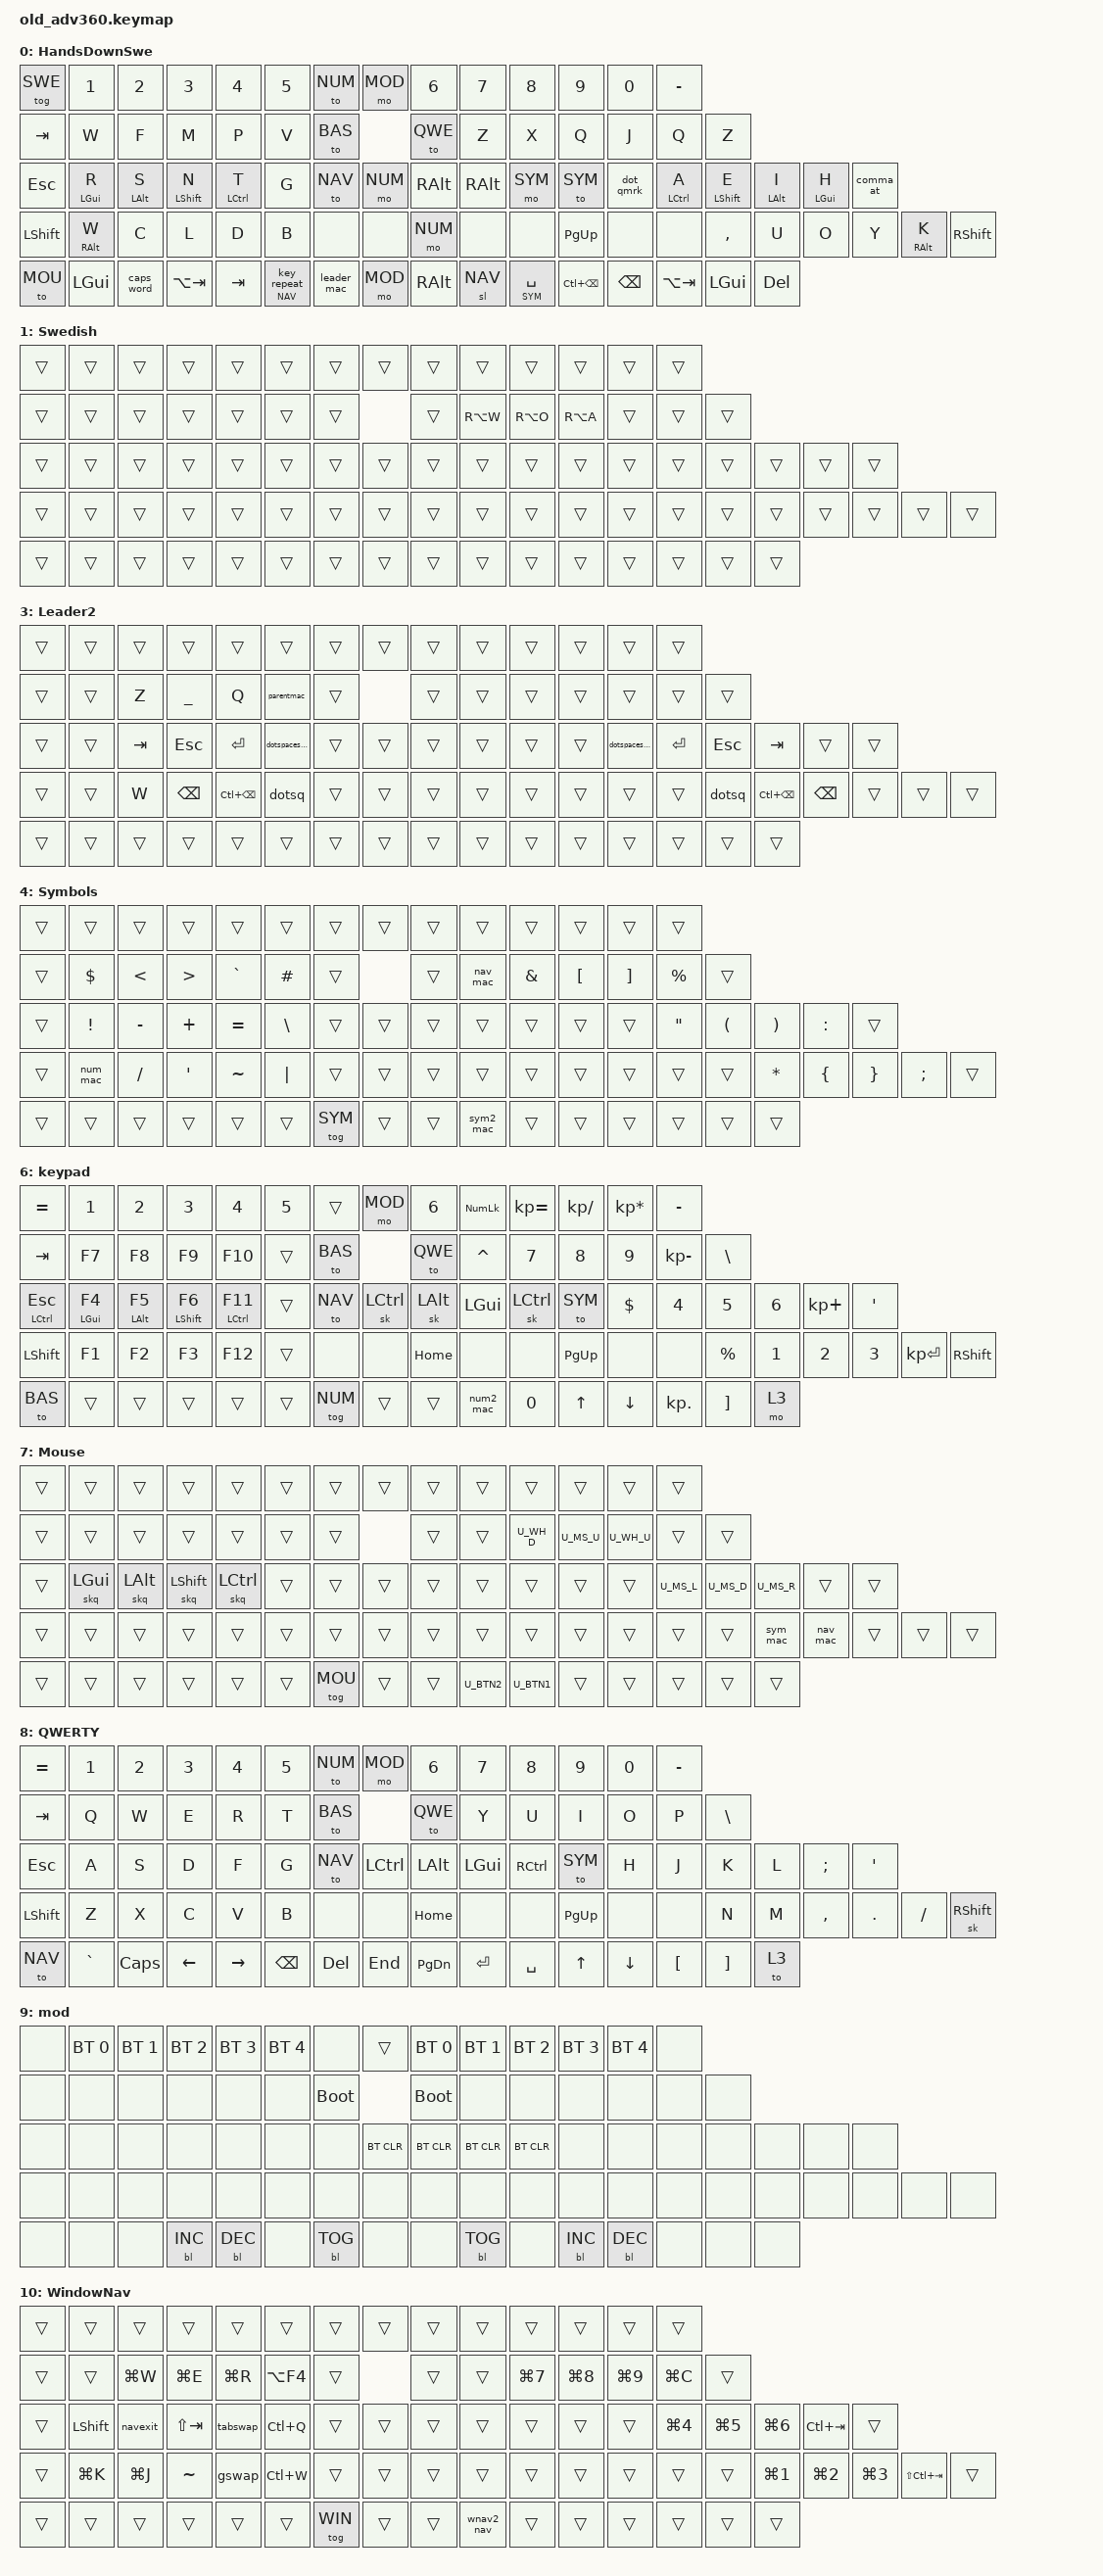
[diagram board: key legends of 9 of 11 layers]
#include <behaviors.dtsi>
#include <dt-bindings/led/led.h>
#include <dt-bindings/zmk/backlight.h>
#include <dt-bindings/zmk/bt.h>
#include <dt-bindings/zmk/keys.h>
#include <dt-bindings/zmk/rgb.h>
#include "mouse.dtsi"
#include "../zmk-nodefree-config/helper.h"
#include "keypos_adv360.h"

#define BAS 0
#define SWE 1
#define LE1 2
#define LE2 3
#define SYM 4
#define NAV 5
#define NUM 6
#define MOU 7
#define QWE 8
#define MOD 9
#define WIN 10




/ {
    behaviors {
        tabswap: tabs {
            compatible = "zmk,behavior-tri-state";
            #binding-cells = <0>;
            label = "tabs";
            bindings = <&kt LALT>, <&kp TAB>, <&kt LALT>;
            ignored-key-positions = <LM2>;
        };
        gswap: tabg {
            compatible = "zmk,behavior-tri-state";
            #binding-cells = <0>;
            label = "tabg";
            bindings = <&kt LALT>, <&kp GRAVE>, <&kt LALT>;
            ignored-key-positions = <LB2>;
        };

        gqt: global-quick-tap {
            compatible = "zmk,behavior-hold-tap";
            label = "GLOBAL_QUICK_TAP";
            #binding-cells = <2>;
            flavor = "tap-preferred";
            tapping-term-ms = <225>;
            quick-tap-ms = <200>;
            global-quick-tap;
            bindings =
                <&kp>,
                <&kp>;
        };
        gql: global-quick-tap-layer {
            compatible = "zmk,behavior-hold-tap";
            label = "GLOBAL_QUICK_TAP_LAYER";
            #binding-cells = <2>;
            flavor = "tap-preferred";
            tapping-term-ms = <225>;
            quick-tap-ms = <200>;
            global-quick-tap;
            bindings =
                <&mo>,
                <&kp>;
        };
        gqr: global-quick-tap-layer-repeat {
            compatible = "zmk,behavior-hold-tap";
            label = "GLOBAL_QUICK_TAP_LAYER_REPEAT";
            #binding-cells = <2>;
            flavor = "tap-preferred";
            tapping-term-ms = <225>;
            quick-tap-ms = <200>;
            global-quick-tap;
            bindings =
                <&mo>,
                <&key_repeat>;
        };
        dot_qmrk: dot_qmrk {
            compatible = "zmk,behavior-mod-morph";
            label = "dot_qmrk";
            #binding-cells = <0>;
            bindings =
                <&kp DOT>,
                <&kp QUESTION>;

            mods = <(MOD_LSFT|MOD_RSFT)>;
        };
        comma_at: comma_at {
            compatible = "zmk,behavior-mod-morph";
            label = "comma_at";
            #binding-cells = <0>;
            bindings =
                <&kp COMMA>,
                <&kp AT>;

            mods = <(MOD_LSFT|MOD_RSFT)>;
        };
        comma_excl: comma_excl {
            compatible = "zmk,behavior-mod-morph";
            label = "comma_excl";
            #binding-cells = <0>;
            bindings =
                <&kp COMMA>,
                <&kp EXCL>;

            mods = <(MOD_LSFT|MOD_RSFT)>;
        };
        lpar_bsh: lpar_bsh {
            compatible = "zmk,behavior-mod-morph";
            label = "lpar_bsh";
            #binding-cells = <0>;
            bindings =
                <&kp LEFT_PARENTHESIS>,
                <&kp BACKSLASH>;

            mods = <(MOD_LSFT|MOD_RSFT)>;
        };
        rpar_fsh: rpar_fsh {
            compatible = "zmk,behavior-mod-morph";
            label = "rpar_fsh";
            #binding-cells = <0>;
            bindings =
                <&kp RIGHT_PARENTHESIS>,
                <&kp SLASH>;

            mods = <(MOD_LSFT|MOD_RSFT)>;
        };
        under_minus: under_minus {
            compatible = "zmk,behavior-mod-morph";
            label = "under_minus";
            #binding-cells = <0>;
            bindings =
                <&kp UNDERSCORE>,
                <&kp MINUS>;

            mods = <(MOD_LSFT|MOD_RSFT)>;
        };
        leader_mac: behavior_macro_1 {
            compatible = "zmk,behavior-macro";
            label = "MACRO1";
            tap-ms = <0>;
            wait-ms = <0>;
            #binding-cells = <0>;
            bindings = < &sl LE1 >;
        };
        sym_mac: behavior_macro_2 {
            compatible = "zmk,behavior-macro";
            label = "MACRO2";
            tap-ms = <0>;
            wait-ms = <0>;
            #binding-cells = <0>;
            bindings = < &sl SYM >;
        };
        nav_mac: behavior_macro_3 {
            compatible = "zmk,behavior-macro";
            label = "MACRO3";
            tap-ms = <0>;
            wait-ms = <0>;
            #binding-cells = <0>;
            bindings = < &sl NAV >;
        };
        num_mac: behavior_macro_4 {
            compatible = "zmk,behavior-macro";
            label = "MACRO4";
            tap-ms = <0>;
            wait-ms = <0>;
            #binding-cells = <0>;
            bindings = < &sl NUM >;
        };
        lead2_mac: behavior_macro_5 {
            compatible = "zmk,behavior-macro";
            label = "MACRO5";
            tap-ms = <0>;
            wait-ms = <0>;
            #binding-cells = <0>;
            bindings = < &sl LE2 >;
        };
        sym2_mac: behavior_macro_6 {
            compatible = "zmk,behavior-macro";
            label = "MACRO6";
            tap-ms = <0>;
            wait-ms = <0>;
            #binding-cells = <0>;
            bindings = < &tog SYM  &sl NAV>;
        };
        nav2_mac: behavior_macro_7 {
            compatible = "zmk,behavior-macro";
            label = "MACRO7";
            tap-ms = <0>;
            wait-ms = <0>;
            #binding-cells = <0>;
            bindings = < &tog NAV  &sl LE2>;
        };
        num2_mac: behavior_macro_8 {
            compatible = "zmk,behavior-macro";
            label = "MACRO8";
            tap-ms = <0>;
            wait-ms = <0>;
            #binding-cells = <0>;
            bindings = < &tog NUM  &sl NAV>;
        };

        skq: sticky_key_quick_release {
            compatible = "zmk,behavior-sticky-key";
            label = "STICKY_KEY_QUICK_RELEASE";
            #binding-cells = <1>;
            bindings = <&kp>;
            release-after-ms = <1000>;
            quick-release;
            ignore-modifiers;
        };
        gnum: behavior_macro_9 {
            compatible = "zmk,behavior-macro";
            label = "MACRO9";
            #binding-cells = <0>;
            bindings = < &skq LEFT_SHIFT >, < &sl NUM >;
        };
        navexit: behavior_macro_10 {
            compatible = "zmk,behavior-macro";
            label = "MACRO10";
            #binding-cells = <0>;
            bindings = < &kp ENTER  &tog WIN >;
        };
        dotspaceshift: behavior_macro_11 {
            compatible = "zmk,behavior-macro";
            label = "MACRO11";
            tap-ms = <0>;
            wait-ms = <0>;
            #binding-cells = <0>;
            bindings = < &kp DOT  &kp SPACE  &skq LEFT_SHIFT >;
        };
        dotsq: behavior_macro_12 {
            compatible = "zmk,behavior-macro";
            label = "MACRO12";
            tap-ms = <0>;
            wait-ms = <0>;
            #binding-cells = <0>;
            bindings = < &kp QUESTION  &kp SPACE  &skq LEFT_SHIFT >;
        };
        parentmac: behavior_macro_13 {
            compatible = "zmk,behavior-macro";
            label = "MACRO13";
            tap-ms = <0>;
            wait-ms = <0>;
            #binding-cells = <0>;
            bindings = < &kp DOT &kp DOT &kp SLASH >;
        };
        leadcaps: behavior_macro_14 {
            compatible = "zmk,behavior-macro";
            label = "MACRO14";
            tap-ms = <0>;
            wait-ms = <0>;
            #binding-cells = <0>;
            bindings = < &tog LE2  &caps_word >;
        };
        cwr: releasable_caps_word {
            compatible = "zmk,behavior-macro";
            label = "RELEASABLECAPSWORD";
            tap-ms = <0>;
            wait-ms = <0>;
            #binding-cells = <0>;
            bindings = <&macro_tap &kp F17 &caps_word>;
        };
        swe: behavior_macro_15 {
            compatible = "zmk,behavior-macro";
            label = "MACRO15";
            tap-ms = <0>;
            wait-ms = <0>;
            #binding-cells = <0>;
            bindings = <&macro_tap &kp F17 &tog SWE>;
        };
        wnav2_nav: behavior_macro_16 {
            compatible = "zmk,behavior-macro";
            label = "MACRO16";
            tap-ms = <0>;
            wait-ms = <0>;
            #binding-cells = <0>;
            bindings = < &tog WIN  &sl NAV >;
        };

    };

    keymap {
        compatible = "zmk,keymap";

        HandsDownSwe {
            bindings = <
        &tog SWE           &kp N1           &kp N2             &kp N3               &kp N4    &kp N5         &to NUM       &mo MOD     &kp N6        &kp N7            &kp N8             &kp N9            &kp N0  &kp MINUS
       &kp TAB            &kp W            &kp F              &kp M                &kp P     &kp V         &to BAS  &to QWE  &kp Z  &kp X  &kp Q      &kp J             &kp Q      &kp Z
 &kp ESCAPE  &gqt LEFT_GUI R  &gqt LEFT_ALT S  &gqt LEFT_SHIFT N  &gqt LEFT_CONTROL T     &kp G         &to NAV  &mo NUM  &kp RALT   &kp RALT  &mo SYM   &to SYM     &dot_qmrk  &gqt LEFT_CONTROL A  &gqt LEFT_SHIFT E  &gqt LEFT_ALT I  &gqt LEFT_GUI H      &comma_at
&kp LEFT_SHIFT      &gqt RALT W            &kp C              &kp L                &kp D     &kp B         &none       &none      &mo NUM         &none             &none          &kp PG_UP             &none      &none  &kp COMMA                &kp U              &kp O            &kp Y      &gqt RALT K  &kp RIGHT_SHIFT
    &to MOU     &kp LEFT_GUI       &caps_word            &kp LA(TAB)          &kp TAB  &gqr NAV 0  &leader_mac       &mo MOD   &kp RALT  &sl NAV         &gql SYM SPACE  &kp LC(BACKSPACE)     &kp BACKSPACE  &kp LA(TAB)  &kp LEFT_GUI           &kp DELETE
            >;
        };
        Swedish {
            bindings = <
&trans  &trans  &trans  &trans  &trans  &trans  &trans /**/ &trans  &trans  &trans  &trans  &trans  &trans  &trans
&trans  &trans  &trans  &trans  &trans  &trans  &trans /**/ &trans  &kp RA(W)  &kp RA(O)  &kp RA(A)   &trans  &trans  &trans
&trans  &trans  &trans  &trans  &trans  &trans  &trans  &trans  &trans /**/ &trans  &trans  &trans  &trans  &trans  &trans  &trans  &trans  &trans
&trans  &trans  &trans  &trans  &trans  &trans  &trans  &trans  &trans  &trans /**/ &trans  &trans  &trans  &trans  &trans  &trans  &trans  &trans  &trans  &trans
&trans  &trans  &trans  &trans  &trans  &trans  &trans  &trans /**/ &trans  &trans  &trans  &trans  &trans  &trans  &trans  &trans
            >;
        };

        Leader {
            bindings = <
&trans  &trans  &trans  &trans  &trans  &trans  &trans /**/ &trans  &trans  &trans  &trans  &trans  &trans  &trans
&trans  &trans  &tog NUM  &tog SYM  &tog NAV  &swe  &trans /**/ &trans  &swe  &tog NAV  &tog SYM  &tog NUM  &trans  &trans
&trans  &skq LEFT_GUI  &skq LEFT_ALT  &skq LEFT_SHIFT  &skq LEFT_CONTROL  &num_mac  &trans  &trans  &trans /**/ &trans    &trans   &trans  &num_mac  &skq LEFT_CONTROL  &skq LEFT_SHIFT  &skq LEFT_ALT  &skq LEFT_GUI  &trans
&trans  &tog WIN  &cwr  &nav_mac  &sym_mac  &tog MOU  &trans  &trans  &trans  &trans /**/ &trans  &trans  &trans  &trans  &tog MOU    &sym_mac  &nav_mac  &cwr  &tog WIN  &trans
&trans  &trans  &trans  &trans  &trans  &trans  &trans  &trans /**/ &trans  &trans  &trans  &trans  &trans  &trans  &trans
            >;
        };
        Leader2 {
            bindings = <
&trans  &trans  &trans  &trans  &trans  &trans  &trans /**/ &trans  &trans  &trans  &trans  &trans  &trans  &trans
&trans  &trans  &kp Z  &kp UNDERSCORE  &kp Q  &parentmac  &trans /**/ &trans  &trans  &trans  &trans  &trans  &trans  &trans
&trans  &trans  &kp TAB  &kp ESCAPE  &kp ENTER  &dotspaceshift  &trans  &trans  &trans /**/ &trans  &trans  &trans  &dotspaceshift  &kp ENTER  &kp ESCAPE  &kp TAB  &trans  &trans
&trans  &trans  &kp W  &kp BACKSPACE  &kp LC(BACKSPACE)  &dotsq  &trans  &trans  &trans  &trans /**/ &trans  &trans  &trans  &trans  &dotsq  &kp LC(BACKSPACE)  &kp BACKSPACE  &trans  &trans  &trans
&trans  &trans  &trans  &trans  &trans  &trans  &trans  &trans /**/ &trans  &trans  &trans  &trans  &trans  &trans  &trans  &trans
            >;
        };

        Symbols {
            bindings = <
&trans           &trans         &trans            &trans     &trans            &trans  &trans  &trans  &trans         &trans            &trans             &trans       &trans  &trans
&trans       &kp DOLLAR  &kp LESS_THAN  &kp GREATER_THAN  &kp GRAVE  &kp HASH  &trans  &trans  &nav_mac  &kp AMPERSAND  &kp LEFT_BRACKET  &kp RIGHT_BRACKET  &kp PERCENT  &trans
&trans  &kp EXCLAMATION      &kp MINUS          &kp PLUS  &kp EQUAL     &kp BACKSLASH  &trans  &trans  &trans                                              &trans       &trans  &trans  &trans  &kp DOUBLE_QUOTES  &kp LEFT_PARENTHESIS  &kp RIGHT_PARENTHESIS  &kp COLON  &trans
&trans        &num_mac      &kp SLASH          &kp SINGLE_QUOTE  &kp TILDE          &kp PIPE  &trans  &trans  &trans         &trans            &trans             &trans       &trans  &trans  &trans       &kp ASTERISK        &kp LEFT_BRACE        &kp RIGHT_BRACE     &kp SEMI  &trans
&trans           &trans         &trans            &trans     &trans            &trans  &tog SYM  &trans  &trans          &sym2_mac            &trans             &trans       &trans  &trans  &trans             &trans
            >;
        };

        Nav {
            bindings = <
       &kp C_BRI_UP     &kp C_BRI_DN    &kp C_PLAY_PAUSE  &kp C_VOLUME_DOWN  &kp C_VOLUME_UP  &kp K_MUTE   &to NUM   &mo MOD  &kp F7   &kp F8     &kp F9          &kp F10        &kp F11       &kp F12
&trans    &kp LC(Q)           &kp LC(BACKSPACE)          &kp UNDERSCORE        &kp AT   &kp LC(T)   &to BAS  &to QWE  &trans  &kp TAB  &kp ENTER        &kp TAB  &trans        &trans
&trans   &skq LEFT_GUI  &skq LEFT_ALT  &skq LEFT_SHIFT  &skq LEFT_CONTROL  &trans  &trans  &trans  &trans  &trans  &trans  &trans  &kp LEFT  &kp DOWN         &kp UP    &kp RIGHT   &trans  &trans
     &trans           &kp BACKSPACE  &kp TAB  &kp ESCAPE  &kp ENTER &trans  &trans   &trans     &trans           &trans         &trans        &trans   &trans  &trans        &trans  &kp HOME  &kp END  &kp PAGE_DOWN  &kp PAGE_UP  &trans
      &trans        &kp C_REWIND  &kp C_FAST_FORWARD         &kp C_PREV  &kp PRINTSCREEN      &trans  &trans  &trans  &trans   &tog NAV     &trans  &trans  &trans   &trans     &to 0
            >;
        };

        keypad {
            bindings = <
           &kp EQUAL            &kp N1        &kp N2        &kp N3          &kp N4         &kp N5     &trans             &mo MOD        &kp N6   &kp KP_NUM  &kp KP_EQUAL  &kp KP_DIVIDE   &kp KP_MULTIPLY   &kp MINUS
             &kp TAB            &kp F7        &kp F8        &kp F9         &kp F10         &trans      &to BAS  &to QWE        &kp CARET       &kp N7        &kp N8         &kp N9      &kp KP_MINUS    &kp BSLH
&mt LEFT_CONTROL ESC            &mt LEFT_GUI F4        &mt LEFT_ALT F5        &mt LEFT_SHIFT F6         &mt LEFT_CONTROL F11         &trans      &to NAV  &sk LEFT_CONTROL  &sk LEFT_ALT                              &kp LEFT_GUI  &sk LEFT_CONTROL       &to SYM    &kp DOLLAR  &kp N4  &kp N5  &kp N6   &kp KP_PLUS    &kp SQT
      &kp LEFT_SHIFT            &kp F1        &kp F2        &kp F3         &kp F12         &trans      &none             &none      &kp HOME        &none         &none      &kp PG_UP             &none       &none    &kp PERCENT  &kp N1  &kp N2  &kp N3  &kp KP_ENTER  &kp RSHFT
               &to BAS          &trans         &trans            &trans     &trans            &trans  &tog NUM            &trans        &trans  &num2_mac        &kp N0         &kp UP          &kp DOWN  &kp KP_DOT  &kp RBKT   &mo 3
            >;
        };

        Mouse {
            bindings = <
&trans  &trans  &trans  &trans  &trans  &trans  &trans /**/ &trans  &trans  &trans  &trans  &trans  &trans  &trans
&trans  &trans  &trans  &trans  &trans  &trans  &trans /**/ &trans  &trans  U_WH_D        U_MS_U         U_WH_U    &trans  &trans
&trans  &skq LEFT_GUI  &skq LEFT_ALT  &skq LEFT_SHIFT  &skq LEFT_CONTROL  &trans  &trans  &trans  &trans /**/ &trans  &trans  &trans  &trans  U_MS_L   U_MS_D   U_MS_R  &trans  &trans
&trans  &trans  &trans  &trans  &trans  &trans  &trans  &trans  &trans  &trans /**/ &trans  &trans  &trans  &trans  &trans  &sym_mac  &nav_mac  &trans  &trans  &trans
&trans  &trans  &trans  &trans  &trans  &trans  &tog MOU  &trans /**/ &trans  U_BTN2        U_BTN1    &trans  &trans  &trans  &trans  &trans
            >;
        };

        QWERTY {
            bindings = <
     &kp EQUAL  &kp NUMBER_1  &kp NUMBER_2  &kp NUMBER_3  &kp NUMBER_4   &kp NUMBER_5       &to NUM      &mo MOD  &kp NUMBER_6  &kp NUMBER_7  &kp NUMBER_8  &kp NUMBER_9  &kp NUMBER_0         &kp MINUS
       &kp TAB         &kp Q         &kp W         &kp E         &kp R          &kp T       &to BAS  &to QWE         &kp Y         &kp U         &kp I         &kp O         &kp P     &kp BACKSLASH
    &kp ESCAPE         &kp A         &kp S         &kp D         &kp F          &kp G       &to NAV  &kp LCTRL      &kp LALT                              &kp LEFT_GUI     &kp RCTRL             &to SYM              &kp H  &kp J      &kp K    &kp L   &kp SEMI  &kp SINGLE_QUOTE
&kp LEFT_SHIFT         &kp Z         &kp X         &kp C         &kp V          &kp B       &none      &none      &kp HOME         &none         &none     &kp PG_UP         &none             &none              &kp N  &kp M  &kp COMMA  &kp DOT  &kp SLASH   &sk RIGHT_SHIFT
         &to NAV     &kp GRAVE  &kp CAPSLOCK      &kp LEFT     &kp RIGHT  &kp BACKSPACE  &kp DELETE    &kp END     &kp PG_DN     &kp ENTER     &kp SPACE        &kp UP      &kp DOWN  &kp LEFT_BRACKET  &kp RIGHT_BRACKET  &to 3
            >;
        };
        mod {
            bindings = <
&none  &bt BT_SEL 0  &bt BT_SEL 1  &bt BT_SEL 2  &bt BT_SEL 3     &bt BT_SEL 4                   &none       &trans  &bt BT_SEL 0  &bt BT_SEL 1     &bt BT_SEL 2  &bt BT_SEL 3  &bt BT_SEL 4                   &none
&none         &none         &none         &none         &none            &none             &bootloader  &bootloader         &none         &none            &none         &none         &none                   &none
&none         &none         &none         &none         &none            &none  &none   &bt BT_CLR    &bt BT_CLR                                   &bt BT_CLR    &bt BT_CLR  &none  &none  &none  &none  &none  &none  &none
&none         &none         &none         &none         &none            &none                   &none        &none         &none         &none            &none         &none         &none                   &none  &none  &none  &none  &none  &none  &none
&none         &none         &none    &bl BL_INC    &bl BL_DEC  &none              &bl BL_TOG        &none         &none    &bl BL_TOG  &none    &bl BL_INC    &bl BL_DEC                   &none  &none  &none
            >;
        };
        WindowNav {
            bindings = <
&trans  &trans  &trans  &trans  &trans  &trans  &trans /**/ &trans  &trans  &trans  &trans  &trans  &trans  &trans
&trans  &trans  &kp LG(W)  &kp LG(E)  &kp LG(R)  &kp LA(F4)  &trans /**/ &trans  &trans  &kp LG(N7)  &kp LG(N8)   &kp LG(N9)  &kp LG(C)  &trans
&trans  &kp LEFT_SHIFT  &navexit  &kp LS(TAB)  &tabswap  &kp LC(Q)  &trans  &trans  &trans /**/ &trans  &trans  &trans  &trans  &kp LG(N4)  &kp LG(N5)  &kp LG(N6)  &kp LC(TAB)  &trans
&trans  &kp LG(K)  &kp LG(J)  &kp TILDE  &gswap  &kp LC(W)  &trans  &trans  &trans  &trans /**/ &trans  &trans  &trans  &trans  &trans  &kp LG(N1)  &kp LG(N2)  &kp LG(N3)  &kp LS(LC(TAB))  &trans
&trans  &trans  &trans  &trans  &trans  &trans  &tog WIN  &trans /**/ &trans  &wnav2_nav  &trans  &trans  &trans  &trans  &trans  &trans
            >;
        };
    };
};
